AUTOSAR XML (schema 00051)
package /ComponentTypes
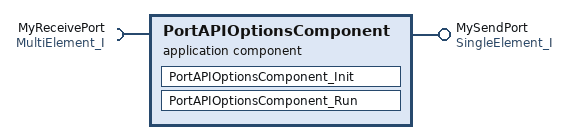
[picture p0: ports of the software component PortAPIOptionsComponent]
  application sw component type PortAPIOptionsComponent
    require port MyReceivePort: required-com-specs=[{data-element=Value1, init-value=65535}, {data-element=Value2, init-value=255}], required-interface=MultiElement_I
    provide port MySendPort: nonqueued-sender-com-spec{data-element=Value, init-value=65535}, provided-interface=SingleElement_I
    behavior PortAPIOptionsComponent_InternalBehavior
      port-api-options:
        enable-take-address=true, indirect-api=false, port=MyReceivePort
        enable-take-address=true, indirect-api=false, port=MySendPort
      runnable PortAPIOptionsComponent_Init
      runnable PortAPIOptionsComponent_Run
  swc implementation PortAPIOptionsComponent_Implementation: behavior=PortAPIOptionsComponent_InternalBehavior
